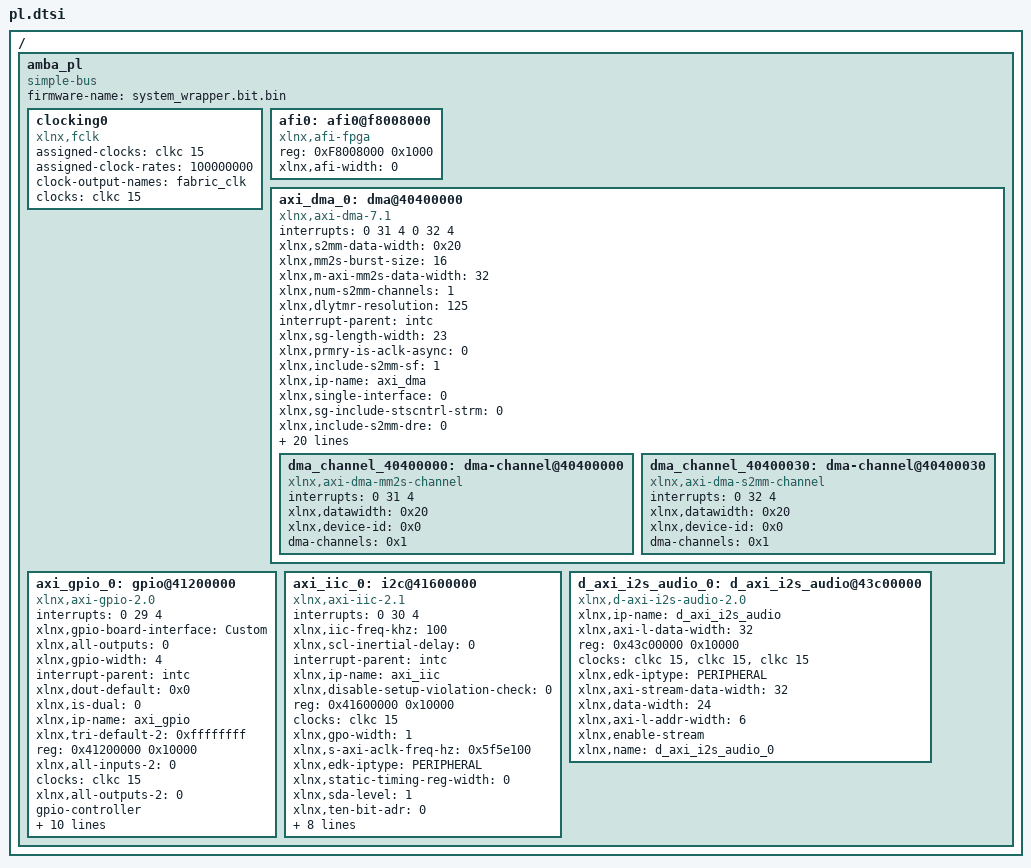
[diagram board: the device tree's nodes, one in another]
/ {
	amba_pl: amba_pl {
		ranges;
		compatible = "simple-bus";
		#address-cells = <1>;
		#size-cells = <1>;
		firmware-name = "system_wrapper.bit.bin";
		clocking0: clocking0 {
			compatible = "xlnx,fclk";
			assigned-clocks = <&clkc 15>;
			assigned-clock-rates = <100000000>;
			#clock-cells = <0>;
			clock-output-names = "fabric_clk";
			clocks = <&clkc 15>;
		};
		afi0: afi0@f8008000 {
			status = "okay";
			compatible = "xlnx,afi-fpga";
			#address-cells = <1>;
			reg = <0xF8008000 0x1000>;
			#size-cells = <0>;
			xlnx,afi-width = <0>;
		};
		axi_dma_0: dma@40400000 {
			interrupts = < 0 31 4 0 32 4 >;
			compatible = "xlnx,axi-dma-7.1" , "xlnx,axi-dma-1.00.a";
			xlnx,s2mm-data-width = <0x20>;
			xlnx,mm2s-burst-size = <16>;
			xlnx,m-axi-mm2s-data-width = <32>;
			xlnx,num-s2mm-channels = <1>;
			xlnx,dlytmr-resolution = <125>;
			interrupt-parent = <&intc>;
			xlnx,sg-length-width = <23>;
			xlnx,prmry-is-aclk-async = <0>;
			xlnx,include-s2mm-sf = <1>;
			#dma-cells = <1>;
			xlnx,ip-name = "axi_dma";
			xlnx,single-interface = <0>;
			xlnx,sg-include-stscntrl-strm = <0>;
			xlnx,include-s2mm-dre = <0>;
			reg = <0x40400000 0x10000>;
			xlnx,addr-width = <32>;
			xlnx,include-s2mm = <1>;
			clocks = <&clkc 15>, <&clkc 15>, <&clkc 15>;
			xlnx,s-axis-s2mm-tdata-width = <32>;
			xlnx,micro-dma = <0>;
			xlnx,increase-throughput = <0>;
			xlnx,mm2s-data-width = <0x20>;
			xlnx,addrwidth = <0x20>;
			xlnx,sg-use-stsapp-length = <0>;
			xlnx,m-axis-mm2s-tdata-width = <32>;
			xlnx,edk-iptype = "PERIPHERAL";
			xlnx,s2mm-burst-size = <16>;
			xlnx,m-axi-s2mm-data-width = <32>;
			xlnx,num-mm2s-channels = <1>;
			xlnx,enable-multi-channel = <0>;
			status = "okay";
			xlnx,include-mm2s-sf = <1>;
			clock-names = "m_axi_mm2s_aclk" , "m_axi_s2mm_aclk" , "s_axi_lite_aclk";
			interrupt-names = "mm2s_introut" , "s2mm_introut";
			xlnx,include-mm2s = <1>;
			xlnx,include-mm2s-dre = <0>;
			xlnx,name = "axi_dma_0";
			dma_channel_40400000: dma-channel@40400000 {
				interrupts = <0 31 4>;
				xlnx,datawidth = <0x20>;
				xlnx,device-id = <0x0>;
				compatible = "xlnx,axi-dma-mm2s-channel";
				dma-channels = <0x1>;
			};
			dma_channel_40400030: dma-channel@40400030 {
				interrupts = <0 32 4>;
				xlnx,datawidth = <0x20>;
				xlnx,device-id = <0x0>;
				compatible = "xlnx,axi-dma-s2mm-channel";
				dma-channels = <0x1>;
			};
		};
		axi_gpio_0: gpio@41200000 {
			#interrupt-cells = <2>;
			interrupts = < 0 29 4 >;
			xlnx,gpio-board-interface = "Custom";
			compatible = "xlnx,axi-gpio-2.0" , "xlnx,xps-gpio-1.00.a";
			xlnx,all-outputs = <0>;
			#gpio-cells = <2>;
			xlnx,gpio-width = <4>;
			interrupt-parent = <&intc>;
			xlnx,dout-default = <0x0>;
			xlnx,is-dual = <0>;
			xlnx,ip-name = "axi_gpio";
			xlnx,tri-default-2 = <0xffffffff>;
			reg = <0x41200000 0x10000>;
			xlnx,all-inputs-2 = <0>;
			clocks = <&clkc 15>;
			xlnx,all-outputs-2 = <0>;
			gpio-controller;
			xlnx,interrupt-present = <1>;
			xlnx,gpio2-board-interface = "Custom";
			xlnx,edk-iptype = "PERIPHERAL";
			xlnx,dout-default-2 = <0x0>;
			status = "okay";
			xlnx,gpio2-width = <32>;
			clock-names = "s_axi_aclk";
			xlnx,use-board-flow;
			interrupt-controller;
			interrupt-names = "ip2intc_irpt";
			xlnx,tri-default = <0xffffffff>;
			xlnx,name = "axi_gpio_0";
			xlnx,all-inputs = <1>;
		};
		axi_iic_0: i2c@41600000 {
			interrupts = < 0 30 4 >;
			xlnx,iic-freq-khz = <100>;
			compatible = "xlnx,axi-iic-2.1" , "xlnx,xps-iic-2.00.a";
			xlnx,scl-inertial-delay = <0>;
			interrupt-parent = <&intc>;
			xlnx,ip-name = "axi_iic";
			xlnx,disable-setup-violation-check = <0>;
			reg = <0x41600000 0x10000>;
			clocks = <&clkc 15>;
			xlnx,gpo-width = <1>;
			xlnx,s-axi-aclk-freq-hz = <0x5f5e100>;
			xlnx,edk-iptype = "PERIPHERAL";
			xlnx,static-timing-reg-width = <0>;
			xlnx,sda-level = <1>;
			status = "okay";
			clock-names = "s_axi_aclk";
			xlnx,ten-bit-adr = <0>;
			xlnx,default-value = <0x0>;
			interrupt-names = "iic2intc_irpt";
			xlnx,iic-board-interface = "Custom";
			xlnx,timing-reg-width = <32>;
			xlnx,iic-freq = <100000>;
			xlnx,smbus-pmbus-host = <0>;
			xlnx,name = "axi_iic_0";
			xlnx,axi-aclk-freq-mhz = "100.0";
			xlnx,sda-inertial-delay = <0>;
		};
		d_axi_i2s_audio_0: d_axi_i2s_audio@43c00000 {
			compatible = "xlnx,d-axi-i2s-audio-2.0";
			xlnx,ip-name = "d_axi_i2s_audio";
			xlnx,axi-l-data-width = <32>;
			reg = <0x43c00000 0x10000>;
			clocks = <&clkc 15>, <&clkc 15>, <&clkc 15>;
			xlnx,edk-iptype = "PERIPHERAL";
			status = "okay";
			xlnx,axi-stream-data-width = <32>;
			xlnx,data-width = <24>;
			clock-names = "AXI_L_aclk" , "M_AXIS_S2MM_ACLK" , "S_AXIS_MM2S_ACLK";
			xlnx,axi-l-addr-width = <6>;
			xlnx,enable-stream;
			xlnx,name = "d_axi_i2s_audio_0";
		};
	};
};
